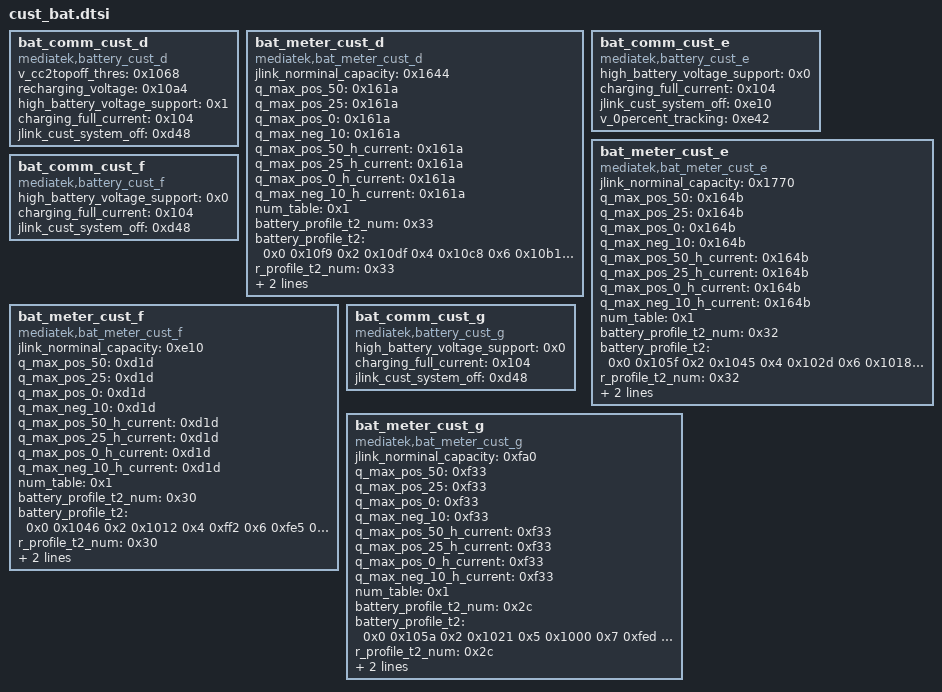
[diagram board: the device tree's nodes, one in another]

		bat_comm_cust_d {
			compatible = "mediatek,battery_cust_d";
			v_cc2topoff_thres = <0x1068>;
			recharging_voltage = <0x10a4>;
			high_battery_voltage_support = <0x1>;
			charging_full_current = <0x104>;
			jlink_cust_system_off = <0xd48>;
		};

		bat_meter_cust_d {
			compatible = "mediatek,bat_meter_cust_d";
			jlink_norminal_capacity = <0x1644>;
			q_max_pos_50 = <0x161a>;
			q_max_pos_25 = <0x161a>;
			q_max_pos_0 = <0x161a>;
			q_max_neg_10 = <0x161a>;
			q_max_pos_50_h_current = <0x161a>;
			q_max_pos_25_h_current = <0x161a>;
			q_max_pos_0_h_current = <0x161a>;
			q_max_neg_10_h_current = <0x161a>;
			num_table = <0x1>;
			battery_profile_t2_num = <0x33>;
			battery_profile_t2 = <0x0 0x10f9 0x2 0x10df 0x4 0x10c8 0x6 0x10b1 0x8 0x109b 0xa 0x1086 0xc 0x1070 0xe 0x105a 0x10 0x1046 0x12 0x1030 0x14 0x101b 0x16 0x1006 0x18 0xff2 0x1a 0xfe1 0x1c 0xfd3 0x1e 0xfb6 0x20 0xfa0 0x22 0xf91 0x24 0xf86 0x26 0xf72 0x28 0xf60 0x2a 0xf4c 0x2c 0xf3b 0x2e 0xf2c 0x30 0xf1e 0x32 0xf13 0x34 0xf09 0x36 0xeff 0x38 0xef6 0x3a 0xeee 0x3c 0xee6 0x3e 0xedf 0x40 0xed9 0x42 0xed3 0x44 0xecc 0x46 0xec5 0x48 0xebe 0x4a 0xeb7 0x4c 0xeb0 0x4e 0xea7 0x50 0xea1 0x52 0xe9a 0x54 0xe91 0x56 0xe86 0x58 0xe7b 0x5a 0xe6d 0x5c 0xe6a 0x5e 0xe67 0x60 0xe5d 0x62 0xe28 0x64 0xdb9>;
			r_profile_t2_num = <0x33>;
			r_profile_t2 = <0x72 0x10f9 0x72 0x10df 0x6c 0x10c8 0x70 0x10b1 0x75 0x109b 0x70 0x1086 0x6d 0x1070 0x62 0x105a 0x68 0x1046 0x77 0x1030 0x6e 0x101b 0x67 0x1006 0x6d 0xff2 0x6f 0xfe1 0x74 0xfd3 0x72 0xfb6 0x7a 0xfa0 0x79 0xf91 0x78 0xf86 0x77 0xf72 0x60 0xf60 0x74 0xf4c 0x68 0xf3b 0x6a 0xf2c 0x68 0xf1e 0x62 0xf13 0x68 0xf09 0x65 0xeff 0x61 0xef6 0x73 0xeee 0x67 0xee6 0x6d 0xedf 0x6b 0xed9 0x79 0xed3 0x71 0xecc 0x66 0xec5 0x69 0xebe 0x71 0xeb7 0x68 0xeb0 0x6b 0xea7 0x70 0xea1 0x73 0xe9a 0x76 0xe91 0x76 0xe86 0x73 0xe7b 0x68 0xe6d 0x6f 0xe6a 0x84 0xe67 0x85 0xe5d 0x83 0xe28 0x81 0xdb9>;
		};

		bat_comm_cust_e {
			compatible = "mediatek,battery_cust_e";
			high_battery_voltage_support = <0x0>;
			charging_full_current = <0x104>;
			jlink_cust_system_off = <0xe10>;
			v_0percent_tracking = <0xe42>;
		};

		bat_meter_cust_e {
			compatible = "mediatek,bat_meter_cust_e";
			jlink_norminal_capacity = <0x1770>;
			q_max_pos_50 = <0x164b>;
			q_max_pos_25 = <0x164b>;
			q_max_pos_0 = <0x164b>;
			q_max_neg_10 = <0x164b>;
			q_max_pos_50_h_current = <0x164b>;
			q_max_pos_25_h_current = <0x164b>;
			q_max_pos_0_h_current = <0x164b>;
			q_max_neg_10_h_current = <0x164b>;
			num_table = <0x1>;
			battery_profile_t2_num = <0x32>;
			battery_profile_t2 = <0x0 0x105f 0x2 0x1045 0x4 0x102d 0x6 0x1018 0x8 0x1005 0xa 0xff3 0xc 0xfe4 0xe 0xfd3 0x10 0xfc2 0x13 0xfb2 0x15 0xfa3 0x17 0xf96 0x19 0xf89 0x1b 0xf7b 0x1d 0xf70 0x1f 0xf63 0x21 0xf57 0x23 0xf4b 0x25 0xf40 0x27 0xf33 0x29 0xf26 0x2b 0xf1a 0x2d 0xf0c 0x2f 0xeff 0x31 0xef5 0x33 0xeec 0x36 0xee5 0x38 0xede 0x3a 0xed9 0x3c 0xed3 0x3e 0xece 0x40 0xeca 0x42 0xec6 0x44 0xec2 0x46 0xec0 0x48 0xebd 0x4a 0xeb9 0x4c 0xeb5 0x4e 0xeb1 0x50 0xeab 0x52 0xea4 0x54 0xe9d 0x56 0xe95 0x59 0xe8b 0x5b 0xe7f 0x5d 0xe6f 0x5f 0xe66 0x61 0xe62 0x63 0xe5e 0x64 0xe48>;
			r_profile_t2_num = <0x32>;
			r_profile_t2 = <0x6d 0x105f 0x6d 0x1045 0x66 0x102d 0x66 0x1018 0x72 0x1005 0x67 0xff3 0x6b 0xfe4 0x73 0xfd3 0x6e 0xfc2 0x74 0xfb2 0x70 0xfa3 0x73 0xf96 0x75 0xf89 0x67 0xf7b 0x6f 0xf70 0x70 0xf63 0x75 0xf57 0x75 0xf4b 0x7e 0xf40 0x79 0xf33 0x81 0xf26 0x7e 0xf1a 0x72 0xf0c 0x6a 0xeff 0x6a 0xef5 0x65 0xeec 0x63 0xee5 0x69 0xede 0x6b 0xed9 0x67 0xed3 0x6f 0xece 0x6d 0xeca 0x70 0xec6 0x6a 0xec2 0x74 0xec0 0x6a 0xebd 0x63 0xeb9 0x6a 0xeb5 0x69 0xeb1 0x70 0xeab 0x69 0xea4 0x6c 0xe9d 0x6f 0xe95 0x73 0xe8b 0x6f 0xe7f 0x6e 0xe6f 0x64 0xe66 0x6a 0xe62 0x6d 0xe5e 0x70 0xe48>;
		};

		bat_comm_cust_f {
			compatible = "mediatek,battery_cust_f";
			high_battery_voltage_support = <0x0>;
			charging_full_current = <0x104>;
			jlink_cust_system_off = <0xd48>;
		};

		bat_meter_cust_f {
			compatible = "mediatek,bat_meter_cust_f";
			jlink_norminal_capacity = <0xe10>;
			q_max_pos_50 = <0xd1d>;
			q_max_pos_25 = <0xd1d>;
			q_max_pos_0 = <0xd1d>;
			q_max_neg_10 = <0xd1d>;
			q_max_pos_50_h_current = <0xd1d>;
			q_max_pos_25_h_current = <0xd1d>;
			q_max_pos_0_h_current = <0xd1d>;
			q_max_neg_10_h_current = <0xd1d>;
			num_table = <0x1>;
			battery_profile_t2_num = <0x30>;
			battery_profile_t2 = <0x0 0x1046 0x2 0x1012 0x4 0xff2 0x6 0xfe5 0x9 0xfdd 0xb 0xfd6 0xd 0xfd2 0xf 0xfd2 0x11 0xfcf 0x13 0xfcf 0x15 0xfcc 0x18 0xfcc 0x1a 0xfca 0x1c 0xfc9 0x1e 0xfc4 0x20 0xfc1 0x22 0xfbe 0x24 0xfb8 0x27 0xfb0 0x29 0xfa3 0x2b 0xf92 0x2d 0xf7f 0x2f 0xf69 0x31 0xf58 0x33 0xf4b 0x35 0xf41 0x38 0xf39 0x3a 0xf35 0x3c 0xf30 0x3e 0xf2c 0x40 0xf28 0x42 0xf26 0x44 0xf22 0x47 0xf1d 0x49 0xf16 0x4b 0xf0f 0x4d 0xf05 0x4f 0xef9 0x51 0xeee 0x53 0xee1 0x56 0xed2 0x58 0xec0 0x5a 0xeab 0x5c 0xe9e 0x5e 0xe94 0x60 0xe7e 0x62 0xe1a 0x64 0xd9e>;
			r_profile_t2_num = <0x30>;
			r_profile_t2 = <0x7d 0x1046 0x7d 0x1012 0x80 0xff2 0x84 0xfe5 0x89 0xfdd 0x82 0xfd6 0x7b 0xfd2 0x78 0xfd2 0x7a 0xfcf 0x8a 0xfcf 0x88 0xfcc 0x86 0xfcc 0x8e 0xfca 0x94 0xfc9 0x92 0xfc4 0x8f 0xfc1 0x8b 0xfbe 0x97 0xfb8 0xab 0xfb0 0xad 0xfa3 0x96 0xf92 0x93 0xf7f 0x8a 0xf69 0x8e 0xf58 0x7d 0xf4b 0x7c 0xf41 0x78 0xf39 0x82 0xf35 0x8b 0xf30 0x7a 0xf2c 0x84 0xf28 0x8e 0xf26 0x92 0xf22 0x83 0xf1d 0x96 0xf16 0x8a 0xf0f 0x89 0xf05 0x94 0xef9 0x7d 0xeee 0x96 0xee1 0x83 0xed2 0x90 0xec0 0x86 0xeab 0x91 0xe9e 0x99 0xe94 0x9a 0xe7e 0x97 0xe1a 0xa2 0xd9e>;
		};

		bat_comm_cust_g {
			compatible = "mediatek,battery_cust_g";
			high_battery_voltage_support = <0x0>;
			charging_full_current = <0x104>;
			jlink_cust_system_off = <0xd48>;
		};

		bat_meter_cust_g {
			compatible = "mediatek,bat_meter_cust_g";
			jlink_norminal_capacity = <0xfa0>;
			q_max_pos_50 = <0xf33>;
			q_max_pos_25 = <0xf33>;
			q_max_pos_0 = <0xf33>;
			q_max_neg_10 = <0xf33>;
			q_max_pos_50_h_current = <0xf33>;
			q_max_pos_25_h_current = <0xf33>;
			q_max_pos_0_h_current = <0xf33>;
			q_max_neg_10_h_current = <0xf33>;
			num_table = <0x1>;
			battery_profile_t2_num = <0x2c>;
			battery_profile_t2 = <0x0 0x105a 0x2 0x1021 0x5 0x1000 0x7 0xfed 0x9 0xfe0 0xc 0xfd7 0xe 0xfd2 0x10 0xfcd 0x13 0xfc9 0x15 0xfc5 0x17 0xfc1 0x19 0xfbc 0x1c 0xfb4 0x1e 0xfab 0x20 0xf9f 0x23 0xf91 0x25 0xf80 0x27 0xf72 0x2a 0xf62 0x2c 0xf53 0x2e 0xf42 0x31 0xf37 0x33 0xf2e 0x35 0xf25 0x38 0xf1e 0x3a 0xf17 0x3c 0xf0e 0x3f 0xf04 0x41 0xefc 0x43 0xef2 0x45 0xee5 0x48 0xed7 0x4a 0xec4 0x4c 0xea8 0x4f 0xe84 0x51 0xe5f 0x53 0xe40 0x56 0xe24 0x58 0xe0e 0x5a 0xdf8 0x5d 0xde2 0x5f 0xdc9 0x61 0xdb2 0x64 0xda0>;
			r_profile_t2_num = <0x2c>;
			r_profile_t2 = <0x8a 0x105a 0x8a 0x1021 0x80 0x1000 0x7e 0xfed 0x7d 0xfe0 0x77 0xfd7 0x75 0xfd2 0x7a 0xfcd 0x83 0xfc9 0x80 0xfc5 0x8a 0xfc1 0x8a 0xfbc 0x88 0xfb4 0x93 0xfab 0x97 0xf9f 0x8f 0xf91 0x93 0xf80 0x90 0xf72 0x94 0xf62 0x8e 0xf53 0x87 0xf42 0x85 0xf37 0x7c 0xf2e 0x7c 0xf25 0x80 0xf1e 0x78 0xf17 0x7c 0xf0e 0x73 0xf04 0x82 0xefc 0x7c 0xef2 0x7f 0xee5 0x8e 0xed7 0x8c 0xec4 0x85 0xea8 0x7b 0xe84 0x78 0xe5f 0x7c 0xe40 0x7c 0xe24 0x79 0xe0e 0x82 0xdf8 0x85 0xde2 0x78 0xdc9 0x7c 0xdb2 0x84 0xda0>;
		};
